# M475 register map
File version: 2.0.2.5
Registers are 32-bit, read-write, reset 0x0 unless marked. A register's access mark holds for its fields unless they carry their own. Offsets are from the block's base; [hi:lo] are bit positions; {n}, {i} and the like mark numbered series.

## DMA — DMA Controller
Base 0x4004C000
0x00 STATUS ro reset 0x101F0000 — DMA Status Register
  [0] MASTER_ENABLE
0x04 CFG wo reset not defined — DMA Configuration Register
  [0] MASTER_ENABLE
0x08 CTRLBASEPTR — DMA Control Data Base Pointer Register
  [31:10] CTRL_BASE_PTR
0x0C ALTCTRLBASEPTR ro — DMA Channel Alternate Control Data Base Pointer Register
  [31:0] ALT_CTRL_BASE_PTR
0x14 CHNLSWREQUEST wo reset not defined — DMA Channel Software Request Register
  [31:0] CHNL_SW_REQUEST
0x18 CHNLUSEBURSTSET — DMA Channel Useburst Set Register
  [31:0] CHNL_USEBURST_SET
0x1C CHNLUSEBURSTCLR wo reset not defined — DMA Channel Useburst Clear Register
  [31:0] CHNL_USEBURST_CLR
0x20 CHNLREQMASKSET — DMA Channel Request Mask Set Register
  [31:0] CHNL_REQ_MASK_SET
0x24 CHNLREQMASKCLR wo reset not defined — DMA Channel Request Mask Clear Register
  [31:0] CHNL_REQ_MASK_CLR
0x28 CHNLENABLESET — DMA Channel Enable Set Register
  [31:0] CHNL_ENABLE_SET
0x2C CHNLENABLECLR wo reset not defined — DMA Channel Enable Clear Register
  [31:0] CHNL_ENABLE_CLR
0x30 CHNLPRIALTSET — DMA Channel Primary-Alternate Set Register
  [31:0] CHNL_PRI_ALT_SET
0x34 CHNLPRIALTCLR wo reset not defined — DMA Channel Primary-Alternate Clear Register
  [31:0] CHNL_PRI_ALT_CLR
0x38 CHNLPRIORITYSET — DMA Channel Priority Set Register
  [31:0] CHNL_PRIORITY_SET
0x3C CHNLPRIORITYCLR wo reset not defined — DMA Channel Priority Clear Register
  [31:0] CHNL_PRIORITY_CLR
0x4C ERRCLR — DMA Bus Error Clear Register
  [0] ERR_CLR

## DMAIF — DMA Interrupt Flag
Base 0x4005F000
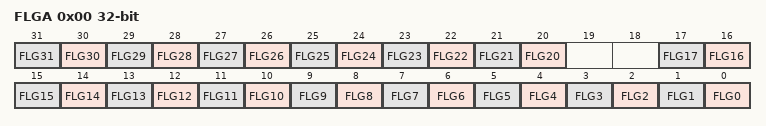
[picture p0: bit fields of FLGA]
0x00 FLGA ro — DMA Flag Register A
  [n] FLG{n} (n=20..31), [n] FLG{n} (n=0..17)

## PA — Port A
Base 0x400C0000
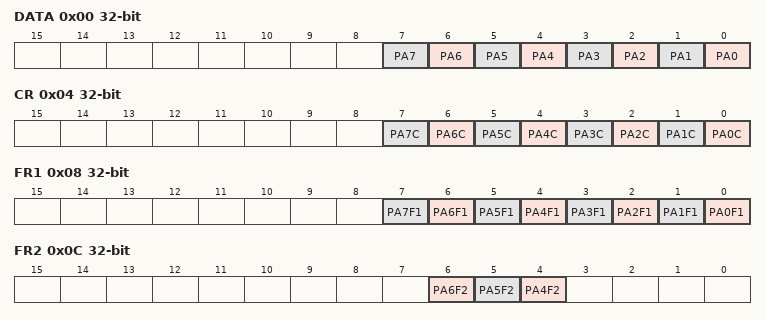
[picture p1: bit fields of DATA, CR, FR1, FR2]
0x00 DATA — Port A Data Register
  [n] PA{n} (n=0..7)
0x04 CR — Port A Output Control Register
  [n] PA{n}C (n=0..7)
0x08 FR1 — Port A Function Register 1
  [n] PA{n}F1 (n=0..7)
0x0C FR2 — Port A Function Register 2
  [6] PA6F2, [5] PA5F2, [4] PA4F2
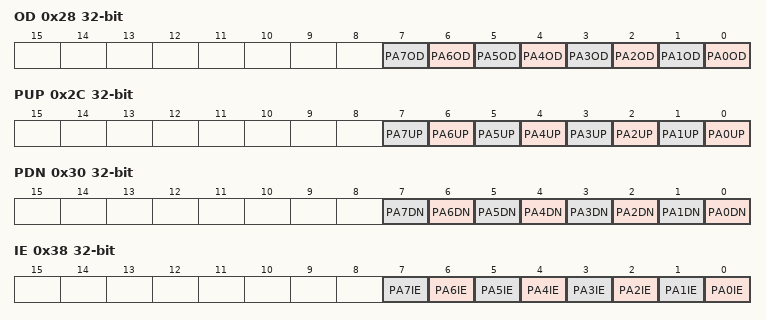
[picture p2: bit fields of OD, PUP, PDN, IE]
0x28 OD — Port A Open Drain Control Register
  [n] PA{n}OD (n=0..7)
0x2C PUP — Port A Pull-up Control Register
  [n] PA{n}UP (n=0..7)
0x30 PDN — Port A Pull-down Control Register
  [n] PA{n}DN (n=0..7)
0x38 IE — Port A Input Control Register
  [n] PA{n}IE (n=0..7)

## PB — Port B
Base 0x400C0100
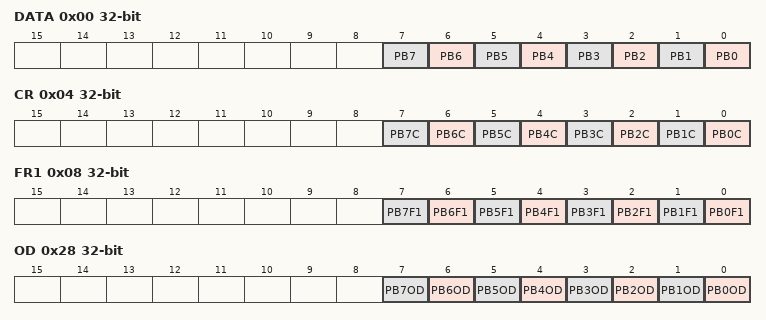
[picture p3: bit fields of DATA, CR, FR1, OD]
0x00 DATA — Port B Data Register
  [n] PB{n} (n=0..7)
0x04 CR — Port B Output Control Register
  [n] PB{n}C (n=0..7)
0x08 FR1 — Port B Function Register 1
  [n] PB{n}F1 (n=0..7)
0x28 OD — Port B Open Drain Control Register
  [n] PB{n}OD (n=0..7)
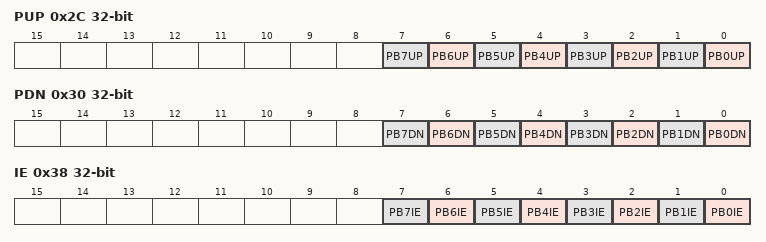
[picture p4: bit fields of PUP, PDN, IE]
0x2C PUP — Port B Pull-up Control Register
  [n] PB{n}UP (n=0..7)
0x30 PDN — Port B Pull-down Control Register
  [n] PB{n}DN (n=0..7)
0x38 IE — Port B Input Control Register
  [n] PB{n}IE (n=0..7)

## PC — Port C
Base 0x400C0200
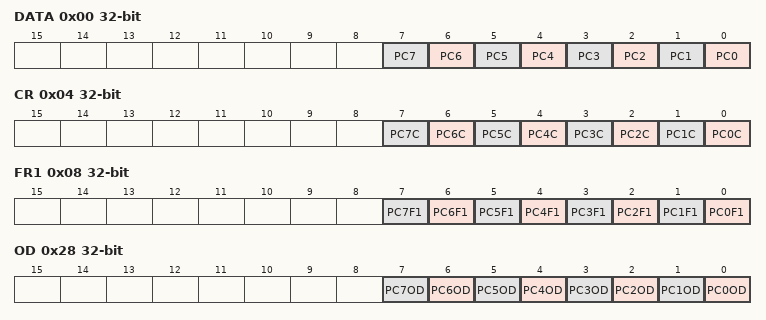
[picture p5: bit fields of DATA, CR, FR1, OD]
0x00 DATA — Port C Data Register
  [n] PC{n} (n=0..7)
0x04 CR — Port C Output Control Register
  [n] PC{n}C (n=0..7)
0x08 FR1 — Port C Function Register 1
  [n] PC{n}F1 (n=0..7)
0x28 OD — Port C Open Drain Control Register
  [n] PC{n}OD (n=0..7)
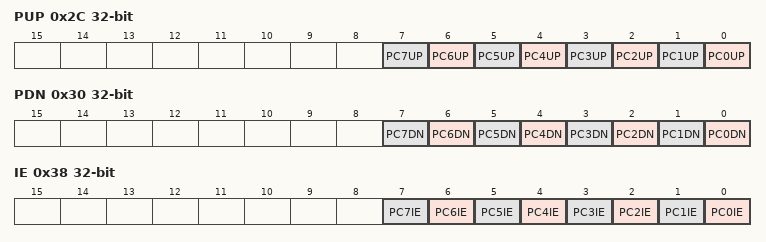
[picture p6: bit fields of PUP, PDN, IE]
0x2C PUP — Port C Pull-up Control Register
  [n] PC{n}UP (n=0..7)
0x30 PDN — Port C Pull-down Control Register
  [n] PC{n}DN (n=0..7)
0x38 IE — Port C Input Control Register
  [n] PC{n}IE (n=0..7)

## PD — Port D
Base 0x400C0300
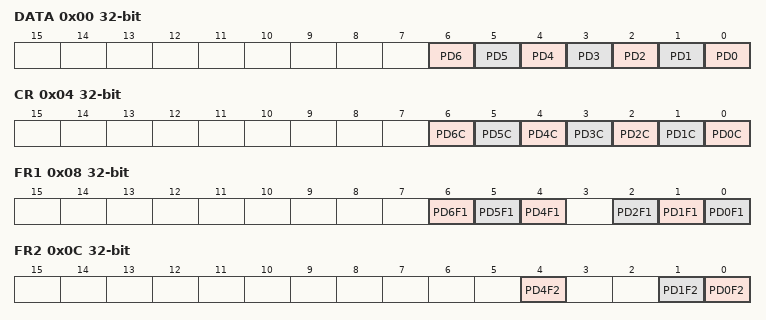
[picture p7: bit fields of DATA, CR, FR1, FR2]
0x00 DATA — Port D Data Register
  [n] PD{n} (n=0..6)
0x04 CR — Port D Output Control Register
  [n] PD{n}C (n=0..6)
0x08 FR1 — Port D Function Register 1
  [6] PD6F1, [5] PD5F1, [4] PD4F1, [2] PD2F1, [1] PD1F1, [0] PD0F1
0x0C FR2 — Port D Function Register 2
  [4] PD4F2, [1] PD1F2, [0] PD0F2
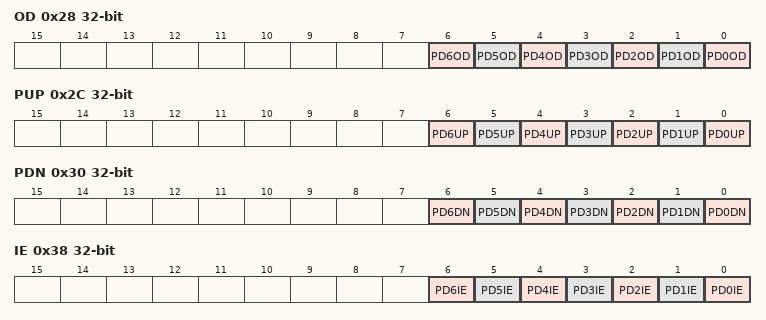
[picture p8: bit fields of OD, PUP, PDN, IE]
0x28 OD — Port D Open Drain Control Register
  [n] PD{n}OD (n=0..6)
0x2C PUP — Port D Pull-up Control Register
  [n] PD{n}UP (n=0..6)
0x30 PDN — Port D Pull-down Control Register
  [n] PD{n}DN (n=0..6)
0x38 IE — Port D Input Control Register
  [n] PD{n}IE (n=0..6)
